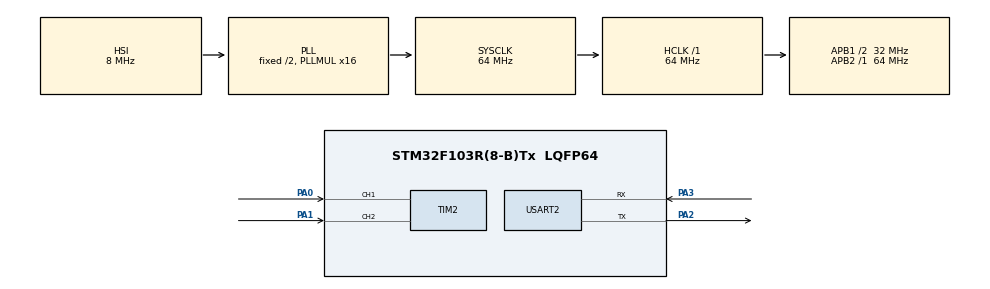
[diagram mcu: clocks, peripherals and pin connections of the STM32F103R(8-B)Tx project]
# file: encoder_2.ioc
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Mcu.Family=STM32F1
Mcu.Name=STM32F103R(8-B)Tx
Mcu.Package=LQFP64
NVIC.PriorityGroup=NVIC_PRIORITYGROUP_4
PA0-WKUP.GPIO_PuPd=GPIO_PULLUP
PA0-WKUP.Signal=S_TIM2_CH1_ETR
PA1.GPIO_PuPd=GPIO_PULLUP
PA1.Signal=S_TIM2_CH2
PA2.Mode=Asynchronous
PA2.Signal=USART2_TX
PA3.Mode=Asynchronous
PA3.Signal=USART2_RX
ProjectManager.HeapSize=0x200
ProjectManager.StackSize=0x400
ProjectManager.TargetToolchain=STM32CubeIDE
RCC.AHBFreq_Value=64000000
RCC.APB1CLKDivider=RCC_HCLK_DIV2
RCC.APB1Freq_Value=32000000
RCC.APB1TimFreq_Value=64000000
RCC.APB2Freq_Value=64000000
RCC.APB2TimFreq_Value=64000000
RCC.HCLKFreq_Value=64000000
RCC.PLLMUL=RCC_PLL_MUL16
RCC.RTCClockSelection=RCC_RTCCLKSOURCE_LSE
RCC.SYSCLKFreq_VALUE=64000000
RCC.SYSCLKSource=RCC_SYSCLKSOURCE_PLLCLK
RCC.USBFreq_Value=64000000
SH.S_TIM2_CH1_ETR.0=TIM2_CH1,Encoder_Interface
SH.S_TIM2_CH2.0=TIM2_CH2,Encoder_Interface
TIM2.EncoderMode=TIM_ENCODERMODE_TI12
TIM2.IC1Filter=10
USART2.VirtualMode=VM_ASYNC
VP_SYS_VS_ND.Mode=No_Debug
board=NUCLEO-F103RB

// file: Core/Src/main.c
/* USER CODE BEGIN Header */
/**
  ******************************************************************************
  * @file           : main.c
  * @brief          : Main program body
  ******************************************************************************
  * @attention
  *
  * Copyright (c) 2026 STMicroelectronics.
  * All rights reserved.
  *
  * This software is licensed under terms that can be found in the LICENSE file
  * in the root directory of this software component.
  * If no LICENSE file comes with this software, it is provided AS-IS.
  *
  ******************************************************************************
  */
/* USER CODE END Header */
#include "main.h"
#include<stdio.h>

TIM_HandleTypeDef htim2;

UART_HandleTypeDef huart2;

/* USER CODE BEGIN PV */

uint32_t lastCount = 0;
/* USER CODE END PV */

void SystemClock_Config(void);
static void MX_GPIO_Init(void);
static void MX_USART2_UART_Init(void);
static void MX_TIM2_Init(void);

int main(void)
{

  /* MCU Configuration--------------------------------------------------------*/

  /* Reset of all peripherals, Initializes the Flash interface and the Systick. */
  HAL_Init();

  /* Configure the system clock */
  SystemClock_Config();

  /* Initialize all configured peripherals */
  MX_GPIO_Init();
  MX_USART2_UART_Init();
  MX_TIM2_Init();
  /* USER CODE BEGIN 2 */
  HAL_TIM_Encoder_Start(&htim2, TIM_CHANNEL_ALL);
  /* USER CODE END 2 */

  /* Infinite loop */
  while (1)
  {
	  uint32_t currentCount = __HAL_TIM_GET_COUNTER(&htim2);

	 	      // 2. Calculate how many pulses happened in the last 100ms
	 	      // (We use int32 to handle reverse rotation correctly)
	 	      int32_t diff = (int32_t)currentCount - (int32_t)lastCount;

	 	      // Handle the 16-bit "wrap around" (if count goes from 65535 to 0)
	 	      if (diff > 32768) diff -= 65536;
	 	      if (diff < -32768) diff += 65536;

	 	      // 3. Convert Pulses-per-100ms to RPM
	 	      // (diff * 10) = pulses per second. Multiply by 60 for minutes.
	 	      float rpm = ((float)diff * 10.0f * 60.0f) / 230;

	 	      // 4. Print results
	 	      printf("Pos: %5lu | RPM: %.2f\r\n", currentCount, rpm);

	 	      // 5. Save current count for next time and wait 100ms
	 	      lastCount = currentCount;
	 	      HAL_Delay(100);
  }
}

void SystemClock_Config(void)
{
  RCC_OscInitTypeDef RCC_OscInitStruct = {0};
  RCC_ClkInitTypeDef RCC_ClkInitStruct = {0};

  /** Initializes the RCC Oscillators according to the specified parameters
  * in the RCC_OscInitTypeDef structure.
  */
  RCC_OscInitStruct.OscillatorType = RCC_OSCILLATORTYPE_HSI;
  RCC_OscInitStruct.HSIState = RCC_HSI_ON;
  RCC_OscInitStruct.HSICalibrationValue = RCC_HSICALIBRATION_DEFAULT;
  RCC_OscInitStruct.PLL.PLLState = RCC_PLL_ON;
  RCC_OscInitStruct.PLL.PLLSource = RCC_PLLSOURCE_HSI_DIV2;
  RCC_OscInitStruct.PLL.PLLMUL = RCC_PLL_MUL16;
  if (HAL_RCC_OscConfig(&RCC_OscInitStruct) != HAL_OK)
  {
    Error_Handler();
  }

  /** Initializes the CPU, AHB and APB buses clocks
  */
  RCC_ClkInitStruct.ClockType = RCC_CLOCKTYPE_HCLK|RCC_CLOCKTYPE_SYSCLK
                              |RCC_CLOCKTYPE_PCLK1|RCC_CLOCKTYPE_PCLK2;
  RCC_ClkInitStruct.SYSCLKSource = RCC_SYSCLKSOURCE_PLLCLK;
  RCC_ClkInitStruct.AHBCLKDivider = RCC_SYSCLK_DIV1;
  RCC_ClkInitStruct.APB1CLKDivider = RCC_HCLK_DIV2;
  RCC_ClkInitStruct.APB2CLKDivider = RCC_HCLK_DIV1;

  if (HAL_RCC_ClockConfig(&RCC_ClkInitStruct, FLASH_LATENCY_2) != HAL_OK)
  {
    Error_Handler();
  }
}

static void MX_TIM2_Init(void)
{

  TIM_Encoder_InitTypeDef sConfig = {0};
  TIM_MasterConfigTypeDef sMasterConfig = {0};

  htim2.Instance = TIM2;
  htim2.Init.Prescaler = 0;
  htim2.Init.CounterMode = TIM_COUNTERMODE_UP;
  htim2.Init.Period = 65535;
  htim2.Init.ClockDivision = TIM_CLOCKDIVISION_DIV1;
  htim2.Init.AutoReloadPreload = TIM_AUTORELOAD_PRELOAD_DISABLE;
  sConfig.EncoderMode = TIM_ENCODERMODE_TI12;
  sConfig.IC1Polarity = TIM_ICPOLARITY_RISING;
  sConfig.IC1Selection = TIM_ICSELECTION_DIRECTTI;
  sConfig.IC1Prescaler = TIM_ICPSC_DIV1;
  sConfig.IC1Filter = 10;
  sConfig.IC2Polarity = TIM_ICPOLARITY_RISING;
  sConfig.IC2Selection = TIM_ICSELECTION_DIRECTTI;
  sConfig.IC2Prescaler = TIM_ICPSC_DIV1;
  sConfig.IC2Filter = 0;
  if (HAL_TIM_Encoder_Init(&htim2, &sConfig) != HAL_OK)
  {
    Error_Handler();
  }
  sMasterConfig.MasterOutputTrigger = TIM_TRGO_RESET;
  sMasterConfig.MasterSlaveMode = TIM_MASTERSLAVEMODE_DISABLE;
  if (HAL_TIMEx_MasterConfigSynchronization(&htim2, &sMasterConfig) != HAL_OK)
  {
    Error_Handler();
  }

}

static void MX_USART2_UART_Init(void)
{

  huart2.Instance = USART2;
  huart2.Init.BaudRate = 115200;
  huart2.Init.WordLength = UART_WORDLENGTH_8B;
  huart2.Init.StopBits = UART_STOPBITS_1;
  huart2.Init.Parity = UART_PARITY_NONE;
  huart2.Init.Mode = UART_MODE_TX_RX;
  huart2.Init.HwFlowCtl = UART_HWCONTROL_NONE;
  huart2.Init.OverSampling = UART_OVERSAMPLING_16;
  if (HAL_UART_Init(&huart2) != HAL_OK)
  {
    Error_Handler();
  }

}

static void MX_GPIO_Init(void)
{

  /* GPIO Ports Clock Enable */
  __HAL_RCC_GPIOA_CLK_ENABLE();

}

/* USER CODE BEGIN 4 */

#ifdef __GNUC__
#define PUTCHAR_PROTOTYPE int __io_putchar(int ch)
#else
#define PUTCHAR_PROTOTYPE int fputc(int ch, FILE *f)
#endif

PUTCHAR_PROTOTYPE
{
  // Replace &huart2 with your specific UART handle if different
  HAL_UART_Transmit(&huart2, (uint8_t *)&ch, 1, 0xFFFF);
  return ch;
}
/* USER CODE END 4 */

void Error_Handler(void)
{
  __disable_irq();
  while (1)
  {
  }
}
